VERSION ""

NS_ :

BS_:

BU_: Sensor_2 Sensor_1 TPMS_ECU

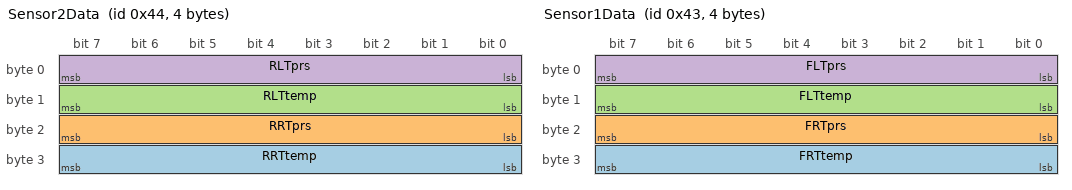
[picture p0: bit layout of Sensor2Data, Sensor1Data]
BO_ 68 Sensor2Data: 4 Sensor_2
 SG_ RRTtemp : 24|8@1- (1,0) [0|0] "" Vector__XXX
 SG_ RRTprs : 16|8@1- (1,0) [0|0] "" Vector__XXX
 SG_ RLTtemp : 8|8@1- (1,0) [0|0] "" Vector__XXX
 SG_ RLTprs : 0|8@1- (1,0) [0|0] "" Vector__XXX

BO_ 67 Sensor1Data: 4 Sensor_1
 SG_ FRTtemp : 24|8@1- (1,0) [0|0] "" Vector__XXX
 SG_ FRTprs : 16|8@1- (1,0) [0|0] "" Vector__XXX
 SG_ FLTtemp : 8|8@1- (1,0) [0|0] "" Vector__XXX
 SG_ FLTprs : 0|8@1- (1,0) [0|0] "" Vector__XXX

BA_DEF_  "BusType" STRING ;
BA_DEF_DEF_  "BusType" "CAN";
